# CY8C5868AXI_LP035 register map
File version: 0.1
CY8C58LP
Registers are 8-bit, read-write, no defined reset value unless marked. A register's access mark holds for its fields unless they carry their own. Offsets are from the block's base; lines under a group give offsets from that group; [hi:lo] are bit positions; {n}, {i} and the like mark numbered series; 'fields as' and 'values as' point back to an identical list; <NAME> marks a mode.

## Memory map
0x400043A4 WaveDAC8_1_BuffAmp size 0x17A2
0x400043A8 IDAC8_1 size 0x17D9
0x400043A8 VDAC8_1 size 0x17DC
0x400043A8 VDAC8_2 size 0x17DA
0x400043A8 WaveDAC8_1_VDAC8 size 0x17DB
0x400043AA ADC_DelSig_1 size 0x17E0
0x40004614 ADC_SAR_2 size 0x158D — SAR ADC
0x40004616 ADC_SAR_1 size 0x158D — SAR ADC
0x400049C8 I2C_1 size 0x19
0x40006409 SPIS_1 size 0x161
0x40006422 PWM_6 size 0x72
0x40006424 PWM_7 size 0x72
0x40006426 PWM_5 size 0x72
0x4000642A PWM_4 size 0x72
0x4000642C PWM_8 size 0x14F
0x40006462 Status_Reg_1 size 0x31
0x4000646D Status_Reg_3 size 0x31
0x4000647D Control_Reg_3 size 0x1
0x40006524 PWM_1 size 0x72
0x40006526 PWM_2 size 0x72
0x4000652A PWM_3 size 0x72
0x4000656A Status_Reg_2 size 0x31
0x40006577 Control_Reg_1 size 0x1
0x40006579 Control_Reg_2 size 0x1

## ADC_SAR_2 — SAR ADC
Base 0x40004614
0x00 SAR_TR0 — SAR trim register
{0x12EC+i} SAR_CSR{i} (i=0..6) — SAR status and control register {i}
0x150C SAR_SW0 — SAR Analog Routing Register 0
{0x150C+i} SAR_SW{i} (i=2..4) — SAR Analog Routing Register {i}
0x1512 SAR_SW6 — SAR Analog Routing Register 6
0x1513 SAR_CLK — SAR Clock Selection Register
0x158C SAR_WRK 16-bit — SAR working register

## IDAC8_1
Base 0x400043A8
0x00 IDAC8_PM_ACT_CFG — Active Power Mode Configuration Register 8
  [3:0] en_dac — Enable DAC block(s). Populated subsystems are counted from the LSB.
0x10 IDAC8_PM_STBY_CFG — Standby Power Mode Configuration Register 8
  fields as IDAC8_PM_ACT_CFG
0x260 IDAC8_TR
  [7:0] tr — 8 Calibration bits
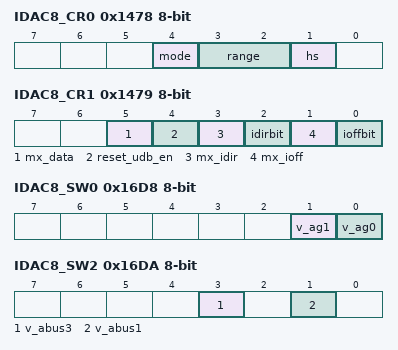
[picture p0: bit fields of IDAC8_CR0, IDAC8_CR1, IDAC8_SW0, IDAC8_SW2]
0x1478 IDAC8_CR0 — DAC Block Control Register 0
  [4] mode ro — Mode Bit
    0=DAC_MODE_V (voltage DAC); 1=DAC_MODE_I (current DAC)
  [3:2] range — Ranges for mode=0 (VDAC) and mode=1 (IDAC)
    0=DAC_RANGE_0 (x0=0V to 4*vref (1.024V); 0 to 31.875uA); 1=DAC_RANGE_1 (x1=0V to 16*vref (4.096V); 0 to 255uA); 2=DAC_RANGE_2 (x0=0V to 4*vref (1.024V); 0 to 2.040mA); 3=DAC_RANGE_3 (x1=0V to 16*vref (4.096V); not used)
  [1] hs — High Speed Bit
    0=DAC_HS_LOWPOWER (regular (low power)); 1=DAC_HS_HIGHSPEED (high speed (higher power))
0x1479 IDAC8_CR1 — DAC Block Control Register 1
  [5] mx_data — Select DATA source
    0=MX_DATA_REG (Select register source); 1=MX_DATA_UDB (Select UDB source)
  [4] reset_udb_en — DAC reset enable
    0=RESET_UDB_EN_DISABLE (Disable DAC Reset Source from UDB); 1=RESET_UDB_EN_ENABLE (Enable DAC Reset Source from UDB)
  [3] mx_idir — Mux selection for DAC current direction control
    0=MX_IDIR_REG (Register source idirbit selected); 1=MX_IDIR_UDB (UDB ictrl selected)
  [2] idirbit — register source for DAC current direction
  [1] mx_ioff — Mux selection for DAC current off control
    0=MX_IOFF_REG (Register source ioffbit selected); 1=MX_IOFF_UDB (UDB ictrl selected)
  [0] ioffbit — register source for DAC current off
0x16D8 IDAC8_SW0 — DAC Analog Routing Register 0
  [1] v_ag1 — Connect voltage output to analog global of same side
    0=AG_NC (not connected); 1=AG_CONNECTED (Connect to Analog Global)
  [0] v_ag0 — Connect voltage output to analog global of same side
    values as v_ag1
0x16DA IDAC8_SW2 — DAC Analog Routing Register 2
  [3] v_abus3 — Connect voltage output to analog (local) bus of the same side
    0=ABUS_NC (not connected); 1=ABUS_CONNECTED (Connect to Analog (local) Bus)
  [1] v_abus1 — Connect voltage output to analog (local) bus of the same side
    values as v_abus3
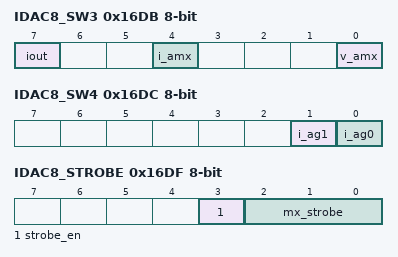
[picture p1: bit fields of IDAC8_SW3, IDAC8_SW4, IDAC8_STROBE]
0x16DB IDAC8_SW3 — DAC Analog Routing Register 3
  [7] iout — Connect current output to pad
    0=IOUT_NC (not connected); 1=IOUT_CONNECT (Connect to pad)
  [4] i_amx — Connect current output to Analog Mux Bus
    0=AMX_NC (not connected); 1=AMX_CONNECTED (Connect to AMUXBUS)
  [0] v_amx — Connect voltage output to Analog Mux Bus
    values as i_amx
0x16DC IDAC8_SW4 — DAC Analog Routing Register 4
  [1] i_ag1 — Connect current output to analog global of same side
    values as IDAC8_SW0.v_ag1
  [0] i_ag0 — Connect current output to analog global of same side
    values as IDAC8_SW0.v_ag1
0x16DF IDAC8_STROBE — DAC Strobe Register
  [3] strobe_en — Strobe gating control
    0=disable strobe; 1=enable strobe
  [2:0] mx_strobe — Strobe source selection
    0=MX_STROBE_BUSWRITE (Select bus write strobe source); 1=MX_STROBE_UDB_SRC (Select UDB strobe source); 2=MX_STROBE_NC_2 (NC); 3=MX_STROBE_NC_3 (NC); {v}=MX_STROBE_CLK_A{v-4}_DIG (Select clk_a{v-4}_dig) (v=4..7)
0x17D8 IDAC8_D — DAC Data Register
  [7:0] data — 8 DAC Data bits
